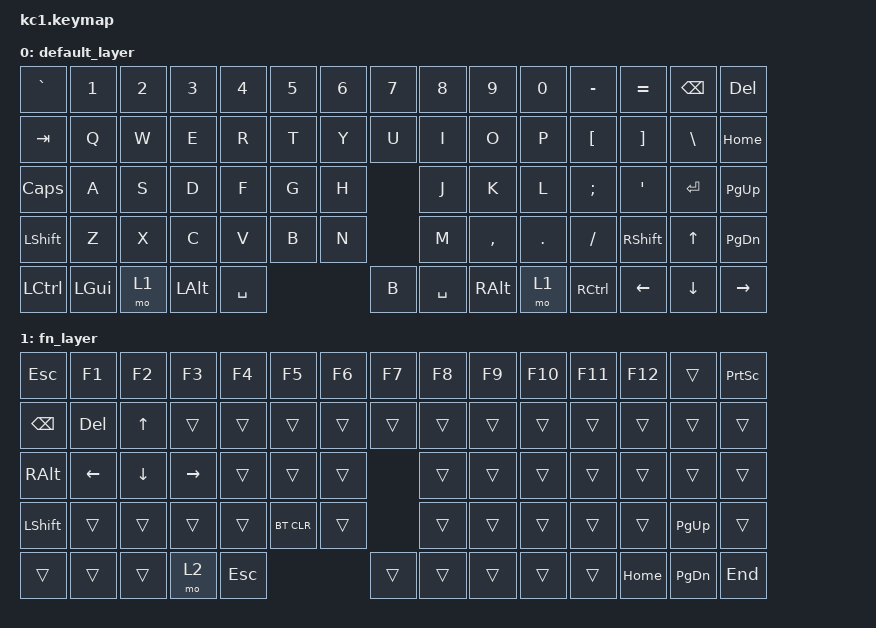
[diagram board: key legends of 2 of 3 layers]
/*
 * Copyright (c) 2020 The ZMK Contributors
 * SPDX-License-Identifier: MIT
 *
 * Board : nice_nano_v2
 * Shield: kc1 (split)
 *
 * Layer 안내
 *  - default_layer : 기본 인풋
 *  - fn_layer      : 기능(Fn) 및 시스템
 *  - fn_layer2     : 출력 토글/BT 선택
 */

#include <behaviors.dtsi>
#include <dt-bindings/zmk/bt.h>
#include <dt-bindings/zmk/keys.h>
#include <dt-bindings/zmk/outputs.h>

/ {
	keymap {
		compatible = "zmk,keymap";

		/* ===========================
		 * default_layer (기본 레이어)
		 *
		 * Row1: [ GRAVE, 1, 2, 3, 4, 5, 6 ] || [ 7, 8, 9, 0, -, =, BSPC, DEL ]
		 * Row2: [ TAB, Q, W, E, R, T ]      || [ Y, U, I, O, P, [, ], \, HOME ]
		 * Row3: [ CAPS, A, S, D, F, G ]     || [ H, J, K, L, ;, ', ENTER, PG_UP ]
		 * Row4: [ LSHFT, Z, X, C, V, B ]    || [ N, M, ,, ., /, RSHFT, UP, PG_DN ]
		 * Row5: [ LCTRL, MO(1), LGUI, LALT, SPACE ] || [ B, SPACE, RALT, MO(1), RCTRL, LEFT, DOWN, RIGHT ]
		 * =========================== */
		default_layer {
			bindings = <
				&kp GRAVE  &kp N1     &kp N2     &kp N3     &kp N4    &kp N5    &kp N6        /**/  &kp N7      &kp N8     &kp N9     &kp N0     &kp MINUS &kp EQUAL &kp BSPC  &kp DEL
				&kp TAB    &kp Q      &kp W      &kp E      &kp R     &kp T                    /**/  &kp Y      &kp U      &kp I      &kp O      &kp P     &kp LBKT  &kp RBKT  &kp BSLH  &kp HOME
				&kp CAPS   &kp A      &kp S      &kp D      &kp F     &kp G                    /**/  &kp H      &kp J      &kp K      &kp L      &kp SEMI  &kp SQT   &kp RET   &kp PG_UP
				&kp LSHFT  &kp Z      &kp X      &kp C      &kp V     &kp B                    /**/  &kp N      &kp M      &kp COMMA  &kp DOT    &kp FSLH  &kp RSHFT &kp UP    &kp PG_DN
				&kp LCTRL  &kp LGUI   &mo 1      &kp LALT   &kp SPACE                         /**/  &kp B       &kp SPACE  &kp RALT   &mo 1      &kp RCTRL &kp LEFT  &kp DOWN  &kp RIGHT
			>;
		};

		/* ===========================
		 * fn_layer (기능/시스템)
		 *
		 * Row1: [ ESC, F1~F6 ] || [ F7~F12, (trans), PSCRN ]
		 * Row2: [ BSPC, DEL, (trans×4) ] || [ (trans×9) ]
		 * Row3: [ (trans×6) ] || [ (trans×8) ]
		 * Row4: [ LSHFT, (trans×4), BT_CLR ] || [ (trans×6), PG_UP, (trans) ]
		 * Row5: [ (trans×2), RALT, MO(2), ESC ] || [ (trans×5), HOME, PG_DN, END ]
		 * =========================== */
		fn_layer {
			bindings = <
				&kp ESC    &kp F1     &kp F2     &kp F3     &kp F4    &kp F5    &kp F6        /**/  &kp F7     &kp F8     &kp F9     &kp F10    &kp F11   &kp F12   &trans     &kp PSCRN
				&kp BSPC   &kp DEL    &kp UP     &trans     &trans    &trans                  /**/  &trans      &trans     &trans     &trans     &trans    &trans    &trans     &trans     &trans
				&kp RALT   &kp LEFT   &kp DOWN   &kp RIGHT  &trans    &trans                  /**/  &trans      &trans     &trans     &trans     &trans    &trans    &trans     &trans
				&kp LSHFT  &trans     &trans     &trans     &trans    &bt BT_CLR              /**/  &trans      &trans     &trans     &trans     &trans    &trans    &kp PG_UP  &trans
				&trans     &trans     &trans     &mo 2      &kp ESC                           /**/  &trans      &trans     &trans     &trans     &trans    &kp HOME  &kp PG_DN  &kp END
			>;
		};

		/* ===========================
		 * fn_layer2 (출력/BT 제어)
		 *
		 * Row1: [ OUT_TOG, BT_SEL 0~4 ] || [ (trans×8) ]
		 * Row2: [ OUT_USB, OUT_BLE, (trans×4) ] || [ (trans×9) ]
		 * Row3: [ (trans×6) ] || [ (trans×8) ]
		 * Row4: [ BT_CLR, (trans×5) ] || [ (trans×8) ]
		 * Row5: [ (trans×5) ] || [ (trans×8) ]
		 * =========================== */
		fn_layer2 {
			bindings = <
				&out OUT_TOG  &bt BT_SEL 0  &bt BT_SEL 1  &bt BT_SEL 2  &bt BT_SEL 3  &bt BT_SEL 4  /**/  &trans  &trans  &trans  &trans  &trans  &trans  &trans  &trans
				&out OUT_USB  &out OUT_BLE &trans        &trans        &trans        &trans        /**/  &trans  &trans  &trans  &trans  &trans  &trans  &trans  &trans  &trans
				&trans         &trans       &trans        &trans        &trans        &trans        /**/  &trans  &trans  &trans  &trans  &trans  &trans  &trans  &trans
				&bt BT_CLR     &trans       &trans        &trans        &trans        &trans        /**/  &trans  &trans  &trans  &trans  &trans  &trans  &trans  &trans
				&trans         &trans       &trans        &trans        &trans        /**/               &trans  &trans  &trans  &trans  &trans  &trans  &trans  &trans
			>;
		};
	};
};

 


